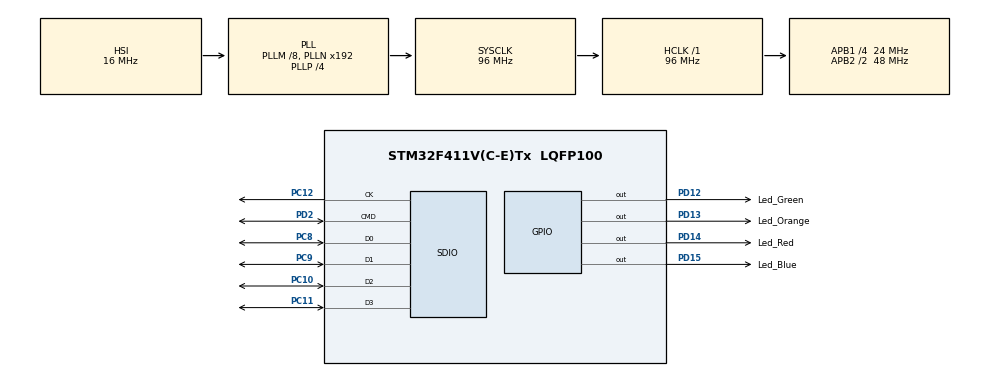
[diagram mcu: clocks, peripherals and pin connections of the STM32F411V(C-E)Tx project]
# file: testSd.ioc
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Mcu.Family=STM32F4
Mcu.Name=STM32F411V(C-E)Tx
Mcu.Package=LQFP100
NVIC.PriorityGroup=NVIC_PRIORITYGROUP_0
NVIC.SDIO_IRQn=true\:0\:0\:false
PC10.Mode=SD_4_bits_Wide_bus
PC10.Signal=SDIO_D2
PC11.Mode=SD_4_bits_Wide_bus
PC11.Signal=SDIO_D3
PC12.Mode=SD_4_bits_Wide_bus
PC12.Signal=SDIO_CK
PC8.Mode=SD_4_bits_Wide_bus
PC8.Signal=SDIO_D0
PC9.Mode=SD_4_bits_Wide_bus
PC9.Signal=SDIO_D1
PD12.GPIO_Label=Led_Green
PD12.Signal=GPIO_Output
PD13.GPIO_Label=Led_Orange
PD13.Signal=GPIO_Output
PD14.GPIO_Label=Led_Red
PD14.Signal=GPIO_Output
PD15.GPIO_Label=Led_Blue
PD15.Signal=GPIO_Output
PD2.Mode=SD_4_bits_Wide_bus
PD2.Signal=SDIO_CMD
ProjectManager.HeapSize=0x400
ProjectManager.StackSize=0x200
ProjectManager.TargetToolchain=TrueSTUDIO
RCC.48MHZClocksFreq_Value=48000000
RCC.AHBFreq_Value=96000000
RCC.APB1CLKDivider=RCC_HCLK_DIV4
RCC.APB1Freq_Value=24000000
RCC.APB1TimFreq_Value=48000000
RCC.APB2CLKDivider=RCC_HCLK_DIV2
RCC.APB2Freq_Value=48000000
RCC.APB2TimFreq_Value=96000000
RCC.CortexFreq_Value=96000000
RCC.HCLKFreq_Value=96000000
RCC.HSE_VALUE=8000000
RCC.HSI_VALUE=16000000
RCC.LSE_VALUE=32768
RCC.PLLI2SM=5
RCC.PLLI2SN=200
RCC.PLLM=8
RCC.PLLP=RCC_PLLP_DIV4
RCC.PLLQ=8
RCC.SYSCLKFreq_VALUE=96000000
RCC.SYSCLKSource=RCC_SYSCLKSOURCE_PLLCLK
RCC.VCOOutputFreq_Value=384000000
SDIO.BusWide=SDIO_BUS_WIDE_1B
SDIO.ClockDiv=255
SDIO.WideMode=SDIO_BUS_WIDE_4B
VP_FATFS_VS_SDIO.Mode=SDIO
board=STM32F411E-DISCO

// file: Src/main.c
/**
  ******************************************************************************
  * File Name          : main.c
  * Description        : Main program body
  ******************************************************************************
  *
  * COPYRIGHT(c) 2016 STMicroelectronics
  *
  * Redistribution and use in source and binary forms, with or without modification,
  * are permitted provided that the following conditions are met:
  *   1. Redistributions of source code must retain the above copyright notice,
  *      this list of conditions and the following disclaimer.
  *   2. Redistributions in binary form must reproduce the above copyright notice,
  *      this list of conditions and the following disclaimer in the documentation
  *      and/or other materials provided with the distribution.
  *   3. Neither the name of STMicroelectronics nor the names of its contributors
  *      may be used to endorse or promote products derived from this software
  *      without specific prior written permission.
  *
  * THIS SOFTWARE IS PROVIDED BY THE COPYRIGHT HOLDERS AND CONTRIBUTORS "AS IS"
  * AND ANY EXPRESS OR IMPLIED WARRANTIES, INCLUDING, BUT NOT LIMITED TO, THE
  * IMPLIED WARRANTIES OF MERCHANTABILITY AND FITNESS FOR A PARTICULAR PURPOSE ARE
  * DISCLAIMED. IN NO EVENT SHALL THE COPYRIGHT HOLDER OR CONTRIBUTORS BE LIABLE
  * FOR ANY DIRECT, INDIRECT, INCIDENTAL, SPECIAL, EXEMPLARY, OR CONSEQUENTIAL
  * DAMAGES (INCLUDING, BUT NOT LIMITED TO, PROCUREMENT OF SUBSTITUTE GOODS OR
  * SERVICES; LOSS OF USE, DATA, OR PROFITS; OR BUSINESS INTERRUPTION) HOWEVER
  * CAUSED AND ON ANY THEORY OF LIABILITY, WHETHER IN CONTRACT, STRICT LIABILITY,
  * OR TORT (INCLUDING NEGLIGENCE OR OTHERWISE) ARISING IN ANY WAY OUT OF THE USE
  * OF THIS SOFTWARE, EVEN IF ADVISED OF THE POSSIBILITY OF SUCH DAMAGE.
  *
  ******************************************************************************
  */
#include "stm32f4xx_hal.h"
#include "fatfs.h"

SD_HandleTypeDef hsd;
HAL_SD_CardInfoTypedef SDCardInfo;

/* USER CODE BEGIN PV */
/* Private variables ---------------------------------------------------------*/

FATFS SDFatFs;  /* File system object for SD disk logical drive */

/* USER CODE END PV */

void SystemClock_Config(void);
static void MX_GPIO_Init(void);
static void MX_SDIO_SD_Init(void);

/* USER CODE BEGIN PFP */
/* Private function prototypes -----------------------------------------------*/

/* USER CODE END PFP */

int main(void)
{

  /* MCU Configuration----------------------------------------------------------*/

  /* Reset of all peripherals, Initializes the Flash interface and the Systick. */
  HAL_Init();

  /* Configure the system clock */
  SystemClock_Config();

  /* Initialize all configured peripherals */
  MX_GPIO_Init();
  MX_SDIO_SD_Init();
  MX_FATFS_Init();

  /* Infinite loop */
  while (1)
  {

  }

}

/** System Clock Configuration
*/
void SystemClock_Config(void)
{

  RCC_OscInitTypeDef RCC_OscInitStruct;
  RCC_ClkInitTypeDef RCC_ClkInitStruct;

  __PWR_CLK_ENABLE();

  __HAL_PWR_VOLTAGESCALING_CONFIG(PWR_REGULATOR_VOLTAGE_SCALE1);

  RCC_OscInitStruct.OscillatorType = RCC_OSCILLATORTYPE_HSI;
  RCC_OscInitStruct.HSIState = RCC_HSI_ON;
  RCC_OscInitStruct.HSICalibrationValue = 16;
  RCC_OscInitStruct.PLL.PLLState = RCC_PLL_ON;
  RCC_OscInitStruct.PLL.PLLSource = RCC_PLLSOURCE_HSI;
  RCC_OscInitStruct.PLL.PLLM = 8;
  RCC_OscInitStruct.PLL.PLLN = 192;
  RCC_OscInitStruct.PLL.PLLP = RCC_PLLP_DIV4;
  RCC_OscInitStruct.PLL.PLLQ = 8;
  HAL_RCC_OscConfig(&RCC_OscInitStruct);

  RCC_ClkInitStruct.ClockType = RCC_CLOCKTYPE_HCLK|RCC_CLOCKTYPE_SYSCLK
                              |RCC_CLOCKTYPE_PCLK1|RCC_CLOCKTYPE_PCLK2;
  RCC_ClkInitStruct.SYSCLKSource = RCC_SYSCLKSOURCE_PLLCLK;
  RCC_ClkInitStruct.AHBCLKDivider = RCC_SYSCLK_DIV1;
  RCC_ClkInitStruct.APB1CLKDivider = RCC_HCLK_DIV4;
  RCC_ClkInitStruct.APB2CLKDivider = RCC_HCLK_DIV2;
  HAL_RCC_ClockConfig(&RCC_ClkInitStruct, FLASH_LATENCY_3);

  HAL_SYSTICK_Config(HAL_RCC_GetHCLKFreq()/1000);

  HAL_SYSTICK_CLKSourceConfig(SYSTICK_CLKSOURCE_HCLK);

  /* SysTick_IRQn interrupt configuration */
  HAL_NVIC_SetPriority(SysTick_IRQn, 0, 0);
}

/* SDIO init function */
void MX_SDIO_SD_Init(void)
{

  hsd.Instance = SDIO;
  hsd.Init.ClockEdge = SDIO_CLOCK_EDGE_RISING;
  hsd.Init.ClockBypass = SDIO_CLOCK_BYPASS_DISABLE;
  hsd.Init.ClockPowerSave = SDIO_CLOCK_POWER_SAVE_DISABLE;
  hsd.Init.BusWide = SDIO_BUS_WIDE_4B;
  hsd.Init.HardwareFlowControl = SDIO_HARDWARE_FLOW_CONTROL_DISABLE;
  hsd.Init.ClockDiv = 255;

}

/** Configure pins as
        * Analog
        * Input
        * Output
        * EVENT_OUT
        * EXTI
*/
void MX_GPIO_Init(void)
{

  GPIO_InitTypeDef GPIO_InitStruct;

  /* GPIO Ports Clock Enable */
  __GPIOD_CLK_ENABLE();
  __GPIOC_CLK_ENABLE();

  /*Configure GPIO pin Output Level */
  HAL_GPIO_WritePin(GPIOD, Led_Green_Pin|Led_Orange_Pin|Led_Red_Pin|Led_Blue_Pin, GPIO_PIN_RESET);

  /*Configure GPIO pins : Led_Green_Pin Led_Orange_Pin Led_Red_Pin Led_Blue_Pin */
  GPIO_InitStruct.Pin = Led_Green_Pin|Led_Orange_Pin|Led_Red_Pin|Led_Blue_Pin;
  GPIO_InitStruct.Mode = GPIO_MODE_OUTPUT_PP;
  GPIO_InitStruct.Pull = GPIO_NOPULL;
  GPIO_InitStruct.Speed = GPIO_SPEED_LOW;
  HAL_GPIO_Init(GPIOD, &GPIO_InitStruct);

}

/************************ (C) COPYRIGHT STMicroelectronics *****END OF FILE****/
